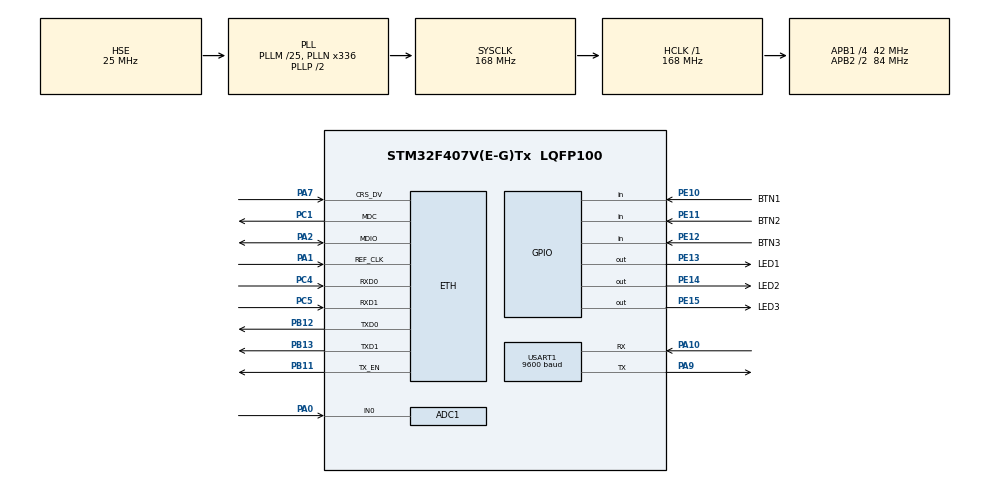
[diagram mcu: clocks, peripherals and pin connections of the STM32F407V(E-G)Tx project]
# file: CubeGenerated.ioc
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ADC1.Channel-1\#ChannelRegularConversion=ADC_CHANNEL_0
ADC1.NbrOfConversion=1
ADC1.NbrOfConversionFlag=1
ADC1.Rank-1\#ChannelRegularConversion=1
ADC1.SamplingTime-1\#ChannelRegularConversion=ADC_SAMPLETIME_480CYCLES
ADC1.master=1
ETH.MediaInterface=HAL_ETH_RMII_MODE
ETH.RxMode=ETH_RXPOLLING_MODE
Mcu.Family=STM32F4
Mcu.Name=STM32F407V(E-G)Tx
Mcu.Package=LQFP100
NVIC.ADC_IRQn=true\:0\:0\:false\:false\:true\:true\:true\:true
NVIC.PriorityGroup=NVIC_PRIORITYGROUP_4
NVIC.TIM7_IRQn=true\:15\:0\:true\:false\:true\:false\:true\:true
NVIC.TimeBase=TIM7_IRQn
NVIC.TimeBaseIP=TIM7
NVIC.USART1_IRQn=true\:10\:0\:true\:false\:true\:true\:true\:true
PA0-WKUP.Signal=ADCx_IN0
PA1.Mode=RMII
PA1.Signal=ETH_REF_CLK
PA10.Mode=Asynchronous
PA10.Signal=USART1_RX
PA13.Mode=Trace_Asynchronous_SW
PA13.Signal=SYS_JTMS-SWDIO
PA14.Mode=Trace_Asynchronous_SW
PA14.Signal=SYS_JTCK-SWCLK
PA2.Mode=RMII
PA2.Signal=ETH_MDIO
PA7.Mode=RMII
PA7.Signal=ETH_CRS_DV
PA9.Mode=Asynchronous
PA9.Signal=USART1_TX
PB11.Mode=RMII
PB11.Signal=ETH_TX_EN
PB12.Mode=RMII
PB12.Signal=ETH_TXD0
PB13.Mode=RMII
PB13.Signal=ETH_TXD1
PB3.Mode=Trace_Asynchronous_SW
PB3.Signal=SYS_JTDO-SWO
PC1.Mode=RMII
PC1.Signal=ETH_MDC
PC4.Mode=RMII
PC4.Signal=ETH_RXD0
PC5.Mode=RMII
PC5.Signal=ETH_RXD1
PE10.GPIO_Label=BTN1
PE10.Signal=GPIO_Input
PE11.GPIO_Label=BTN2
PE11.Signal=GPIO_Input
PE12.GPIO_Label=BTN3
PE12.Signal=GPIO_Input
PE13.GPIO_Label=LED1
PE13.Signal=GPIO_Output
PE14.GPIO_Label=LED2
PE14.Signal=GPIO_Output
PE15.GPIO_Label=LED3
PE15.Signal=GPIO_Output
PH0-OSC_IN.Mode=HSE-External-Oscillator
PH0-OSC_IN.Signal=RCC_OSC_IN
PH1-OSC_OUT.Mode=HSE-External-Oscillator
PH1-OSC_OUT.Signal=RCC_OSC_OUT
ProjectManager.HeapSize=0x2000
ProjectManager.StackSize=0x400
ProjectManager.TargetToolchain=Makefile
RCC.48MHZClocksFreq_Value=48000000
RCC.AHBFreq_Value=168000000
RCC.APB1CLKDivider=RCC_HCLK_DIV4
RCC.APB1Freq_Value=42000000
RCC.APB1TimFreq_Value=84000000
RCC.APB2CLKDivider=RCC_HCLK_DIV2
RCC.APB2Freq_Value=84000000
RCC.APB2TimFreq_Value=168000000
RCC.CortexFreq_Value=168000000
RCC.HCLKFreq_Value=168000000
RCC.HSE_VALUE=25000000
RCC.HSI_VALUE=16000000
RCC.LSE_VALUE=32768
RCC.PLLM=25
RCC.PLLN=336
RCC.PLLQ=7
RCC.PLLSourceVirtual=RCC_PLLSOURCE_HSE
RCC.SYSCLKFreq_VALUE=168000000
RCC.SYSCLKSource=RCC_SYSCLKSOURCE_PLLCLK
RCC.VCOOutputFreq_Value=336000000
SH.ADCx_IN0.0=ADC1_IN0,IN0
USART1.BaudRate=9600
USART1.VirtualMode=VM_ASYNC
VP_RNG_VS_RNG.Mode=RNG_Activate
VP_SYS_VS_tim7.Mode=TIM7
board=custom

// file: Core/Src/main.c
/* USER CODE BEGIN Header */
/**
  ******************************************************************************
  * @file           : main.c
  * @brief          : Main program body
  ******************************************************************************
  * @attention
  *
  * Copyright (c) 2025 STMicroelectronics.
  * All rights reserved.
  *
  * This software is licensed under terms that can be found in the LICENSE file
  * in the root directory of this software component.
  * If no LICENSE file comes with this software, it is provided AS-IS.
  *
  ******************************************************************************
  */
/* USER CODE END Header */
#include "main.h"
#include "adc.h"
#include "usart.h"
#include "gpio.h"

/* USER CODE BEGIN Includes */
#include "system.h"
/* USER CODE END Includes */

void SystemClock_Config(void);

int main(void)
{

  /* MCU Configuration--------------------------------------------------------*/

  /* Reset of all peripherals, Initializes the Flash interface and the Systick. */
  HAL_Init();

  /* Configure the system clock */
  SystemClock_Config();

  /* Initialize all configured peripherals */
  MX_GPIO_Init();
  MX_USART1_UART_Init();
  MX_ADC1_Init();
  /* USER CODE BEGIN 2 */
  SystemRun();
  /* USER CODE END 2 */

  /* Infinite loop */
  while (1)
  {

  }
}

void SystemClock_Config(void)
{
  RCC_OscInitTypeDef RCC_OscInitStruct = {0};
  RCC_ClkInitTypeDef RCC_ClkInitStruct = {0};

  /** Configure the main internal regulator output voltage
  */
  __HAL_RCC_PWR_CLK_ENABLE();
  __HAL_PWR_VOLTAGESCALING_CONFIG(PWR_REGULATOR_VOLTAGE_SCALE1);

  /** Initializes the RCC Oscillators according to the specified parameters
  * in the RCC_OscInitTypeDef structure.
  */
  RCC_OscInitStruct.OscillatorType = RCC_OSCILLATORTYPE_HSE;
  RCC_OscInitStruct.HSEState = RCC_HSE_ON;
  RCC_OscInitStruct.PLL.PLLState = RCC_PLL_ON;
  RCC_OscInitStruct.PLL.PLLSource = RCC_PLLSOURCE_HSE;
  RCC_OscInitStruct.PLL.PLLM = 25;
  RCC_OscInitStruct.PLL.PLLN = 336;
  RCC_OscInitStruct.PLL.PLLP = RCC_PLLP_DIV2;
  RCC_OscInitStruct.PLL.PLLQ = 7;
  if (HAL_RCC_OscConfig(&RCC_OscInitStruct) != HAL_OK)
  {
    Error_Handler();
  }

  /** Initializes the CPU, AHB and APB buses clocks
  */
  RCC_ClkInitStruct.ClockType = RCC_CLOCKTYPE_HCLK|RCC_CLOCKTYPE_SYSCLK
                              |RCC_CLOCKTYPE_PCLK1|RCC_CLOCKTYPE_PCLK2;
  RCC_ClkInitStruct.SYSCLKSource = RCC_SYSCLKSOURCE_PLLCLK;
  RCC_ClkInitStruct.AHBCLKDivider = RCC_SYSCLK_DIV1;
  RCC_ClkInitStruct.APB1CLKDivider = RCC_HCLK_DIV4;
  RCC_ClkInitStruct.APB2CLKDivider = RCC_HCLK_DIV2;

  if (HAL_RCC_ClockConfig(&RCC_ClkInitStruct, FLASH_LATENCY_5) != HAL_OK)
  {
    Error_Handler();
  }
}

void HAL_TIM_PeriodElapsedCallback(TIM_HandleTypeDef *htim)
{
  if (htim->Instance == TIM7) {
    HAL_IncTick();
  }
}

void Error_Handler(void)
{
  __disable_irq();
  while (1)
  {
  }
}
